# STM8TL52F4 register map
Vendor: STMicroelectronics; Series: STM8T; File version: 1.0
8-bit, ultra-low-power, touch-sensing MCUs with 16-Kbyte Flash and proximity detection
CPU: other r1p0, big endian, no MPU, no FPU, 4 interrupt priority bits
Registers are 8-bit, read-write, reset 0x0 unless marked. A register's access mark holds for its fields unless they carry their own. Offsets are from the block's base; lines under a group give offsets from that group; [hi:lo] are bit positions; {n}, {i} and the like mark numbered series; 'fields as' and 'values as' point back to an identical list; <NAME> marks a mode.

## Memory map
0x00004800 OPT blocks up to offset 0x9
0x00005000 PORTA size 0x5
0x00005005 PORTB size 0x5
0x0000500F PORTD size 0x5
0x00005050 FLASH size 0x5
0x000050A0 ITC_EXTI size 0x6
0x000050A6 WFE size 0x2
0x000050B0 RST size 0x2
0x000050C0 CLK blocks up to offset 0x6
0x000050D3 WDG blocks up to offset 0x10
0x000050F0 AWU size 0x3
0x000050F3 BEEP size 0x1
0x00005200 SPI size 0x5
0x00005210 I2C size 0xE
0x00005230 USART size 0x8
0x00005250 TIM2 size 0x16
0x00005280 TIM3 size 0x16
0x000052E0 TIM4 size 0x9
0x00005300 PXS blocks up to offset 0x5A
0x00007F00 CPU blocks up to offset 0x61
0x00007F70 ITC_SPR size 0x8
0x00007F80 SWIM size 0x1
0x00007F90 DM size 0xB

## Interrupts
1 Interrupt_IRQ1 (FLASH) — Interrupt_IRQ1 interrupt
2 Interrupt_IRQ2 (PXS) — Interrupt_IRQ2 interrupt
4 Interrupt_IRQ4 (AWU) — Interrupt_IRQ4 interrupt
19 Interrupt_IRQ19 (TIM2) — Interrupt_IRQ19 interrupt
20 Interrupt_IRQ20 (TIM2) — Interrupt_IRQ20 interrupt
21 Interrupt_IRQ21 (TIM3) — Interrupt_IRQ21 interrupt
22 Interrupt_IRQ22 (TIM3) — Interrupt_IRQ22 interrupt
25 Interrupt_IRQ25 (TIM4) — Interrupt_IRQ25 interrupt
26 Interrupt_IRQ26 (SPI) — Interrupt_IRQ26 interrupt
27 Interrupt_IRQ27 (USART) — Interrupt_IRQ27 interrupt
28 Interrupt_IRQ28 (USART) — Interrupt_IRQ28 interrupt
29 Interrupt_IRQ29 (I2C) — Interrupt_IRQ29 interrupt

## AWU
Base 0x000050F0
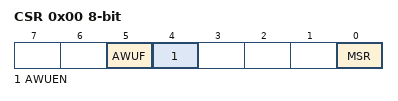
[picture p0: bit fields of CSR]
0x00 CSR — AWU control/status register
  [5] AWUF, [4] AWUEN, [0] MSR
0x01 APR reset 0x3F — AWU asynchronous prescaler buffer register
  [5:0] APR
0x02 TBR — AWU timebase selection register
  [5:0] AWUTB

## BEEP
Base 0x000050F3
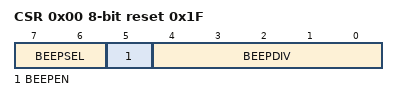
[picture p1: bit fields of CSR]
0x00 CSR reset 0x1F — BEEP control/status register
  [7:6] BEEPSEL, [5] BEEPEN, [4:0] BEEPDIV

## CLK
Base 0x000050C0
0x00 CKDIVR reset 0x3 — Clock divider register
  [1:0] HSIDIV
0x03 PCKENR1 — Peripheral clock gating register 1
0x04 PCKENR2 — Peripheral clock gating register 2
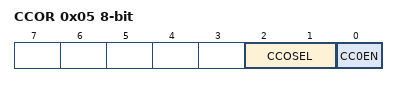
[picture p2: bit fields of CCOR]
0x05 CCOR — Configurable clock control register
  [2:1] CCOSEL, [0] CC0EN

## CPU
Base 0x00007F00
0x00 A — Accumulator
0x01 PCE — Program counter extended
0x02 PCH reset 0x80 — Program counter high
0x03 PCL — Program counter low
0x04 XH — X index register high
0x05 XL — X index register low
0x06 YH — Y index register high
0x07 YL — Y index register low
0x08 SPH reset 0x5 — Stack pointer high
0x09 SPL reset 0xFF — Stack pointer low
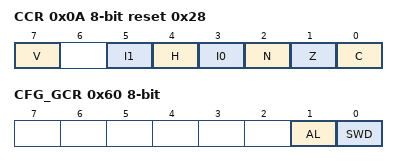
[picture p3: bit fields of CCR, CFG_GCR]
0x0A CCR reset 0x28 — Condition code register
  [7] V, [5] I1, [4] H, [3] I0, [2] N, [1] Z, [0] C
0x60 CFG_GCR — Global configuration register
  [1] AL, [0] SWD

## DM
Base 0x00007F90
0x00 BK1RE reset 0xFF — Breakpoint 1 register extended byte
0x01 BK1RH reset 0xFF — Breakpoint 1 register high byte
0x02 BK1RL reset 0xFF — Breakpoint 1 register low byte
0x03 BK2RE reset 0xFF — Breakpoint 2 register extended byte
0x04 BK2RH reset 0xFF — Breakpoint 2 register high byte
0x05 BK2RL reset 0xFF — Breakpoint 2 register low byte
0x06 CR1 — Debug module control register 1
0x07 CR2 — Debug module control register 2
0x08 CSR1 reset 0x10 — Debug module control/status register 1
0x09 CSR2 — Debug module control/status register 2
0x0A ENFCTR reset 0xFF — Enable function register

## FLASH
Base 0x00005050
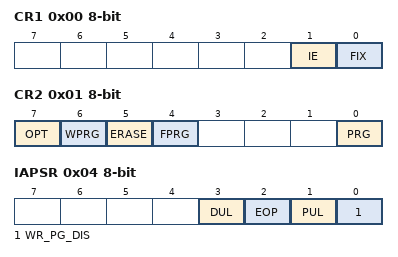
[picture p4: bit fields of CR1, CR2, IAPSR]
0x00 CR1 — Flash control register 1
  [1] IE, [0] FIX
0x01 CR2 — Flash control register 2
  [7] OPT, [6] WPRG, [5] ERASE, [4] FPRG, [0] PRG
0x02 PUKR — Flash Program memory unprotection register
  [7:0] MASS_PRG
0x03 DUKR — Data EEPROM unprotection register
  [7:0] MASS_DATA
0x04 IAPSR — Flash in-application programming status register
  [3] DUL, [2] EOP, [1] PUL, [0] WR_PG_DIS
